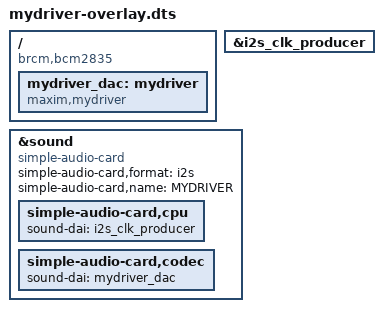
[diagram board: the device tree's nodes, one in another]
// Overlay for Maxim MYDRIVER audio DAC

// dtparams:
//     no-sdmode  - SD_MODE pin not managed by driver.
//     sdmode-pin - Specify GPIO pin to which SD_MODE is connected (default 4).

/dts-v1/;
/plugin/;

/ {
	compatible = "brcm,bcm2835";

	/* Enable I2S */
	fragment@0 {
		target = <&i2s_clk_producer>;
		__overlay__ {
			status = "okay";
		};
	};

	/* DAC whose SD_MODE pin is managed by driver (via GPIO pin) */
	fragment@1 {
		target-path = "/";
		__overlay__ {
			mydriver_dac: mydriver {
				compatible = "maxim,mydriver";
				#sound-dai-cells = <0>;status = "okay";
			};
		};
	};

	/* Soundcard connecting I2S to DAC with SD_MODE */
	fragment@2 {
		target = <&sound>;
		__overlay__ {
			compatible = "simple-audio-card";
			simple-audio-card,format = "i2s";
			simple-audio-card,name = "MYDRIVER";
			status = "okay";
			simple-audio-card,cpu {
				sound-dai = <&i2s_clk_producer>;
			};
			simple-audio-card,codec {
				sound-dai = <&mydriver_dac>;
			};
		};
	};
};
